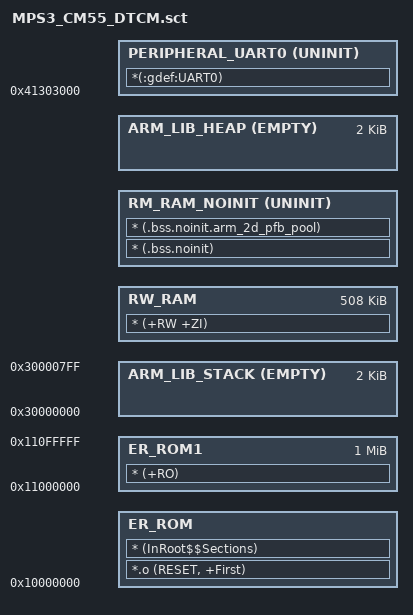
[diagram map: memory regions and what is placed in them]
#! armclang -E --target=arm-arm-none-eabi -mcpu=cortex-m33 -xc
; command above MUST be in first line (no comment above!)

/*
;-------- <<< Use Configuration Wizard in Context Menu >>> -------------------
*/

/*--------------------- Flash Configuration ----------------------------------
; <h> Flash Configuration
;   <o0> Flash Base Address <0x0-0xFFFFFFFF:8>
;   <o1> Flash Size (in Bytes) <0x0-0xFFFFFFFF:8>
; </h>
 *----------------------------------------------------------------------------*/
#define __ROM_BASE     0x10000000
#define __ROM_SIZE     0x00080000

/*--------------------- Flash Configuration ----------------------------------
; <h> Flash Configuration
;   <o0> Flash1 Base Address <0x0-0xFFFFFFFF:8>
;   <o1> Flash1 Size (in Bytes) <0x0-0xFFFFFFFF:8>
; </h>
 *----------------------------------------------------------------------------*/
#define __ROM1_BASE    0x11000000
#define __ROM1_SIZE    0x00100000

/*--------------------- Embedded RAM Configuration ---------------------------
; <h> RAM Configuration
;   <o0> RAM Base Address    <0x0-0xFFFFFFFF:8>
;   <o1> RAM Size (in Bytes) <0x0-0xFFFFFFFF:8>
; </h>
 *----------------------------------------------------------------------------*/
#define __RAM_BASE     0x30000000
#define __RAM_SIZE     0x00080000

#define __HEAP_BASE     +0

/*--------------------- Stack / Heap Configuration ---------------------------
; <h> Stack / Heap Configuration
;   <o0> Stack Size (in Bytes) <0x0-0xFFFFFFFF:8>
;   <o1> Heap Size (in Bytes) <0x0-0xFFFFFFFF:8>
; </h>
 *----------------------------------------------------------------------------*/
#define __HEAP_SIZE     0x00000800
#define __STACK_SIZE    0x00000800

#define __RAM_RW_SIZE 	(__RAM_SIZE - __STACK_SIZE - __HEAP_SIZE)

LR_ROM __ROM_BASE __ROM_SIZE  {                                                 ; load region size_region
    ER_ROM +0 {                                                                 ; load address = execution address
        *.o (RESET, +First)
        * (InRoot$$Sections)
        ;   *(Veneer$$CMSE)                                                     ; uncomment for secure applications
        ;   * (+XO)
    }

    ARM_LIB_STACK __RAM_BASE ALIGN 8 EMPTY __STACK_SIZE {                      ; Reserve empty region for stack
    }

    RW_RAM +0 __RAM_RW_SIZE {
        * (+RW +ZI)
    }

    RM_RAM_NOINIT +0 UNINIT {
        * (.bss.noinit)
        * (.bss.noinit.arm_2d_pfb_pool)
    }

    ARM_LIB_HEAP  __HEAP_BASE ALIGN 8 EMPTY __HEAP_SIZE  {                      ; Reserve empty region for heap
    }
  
    PERIPHERAL_UART0 0x41303000 UNINIT {
        *(:gdef:UART0)
    }
}

LR_ROM1 __ROM1_BASE __ROM1_SIZE {
    ER_ROM1 __ROM1_BASE __ROM1_SIZE {
        * (+RO)
    }
}
